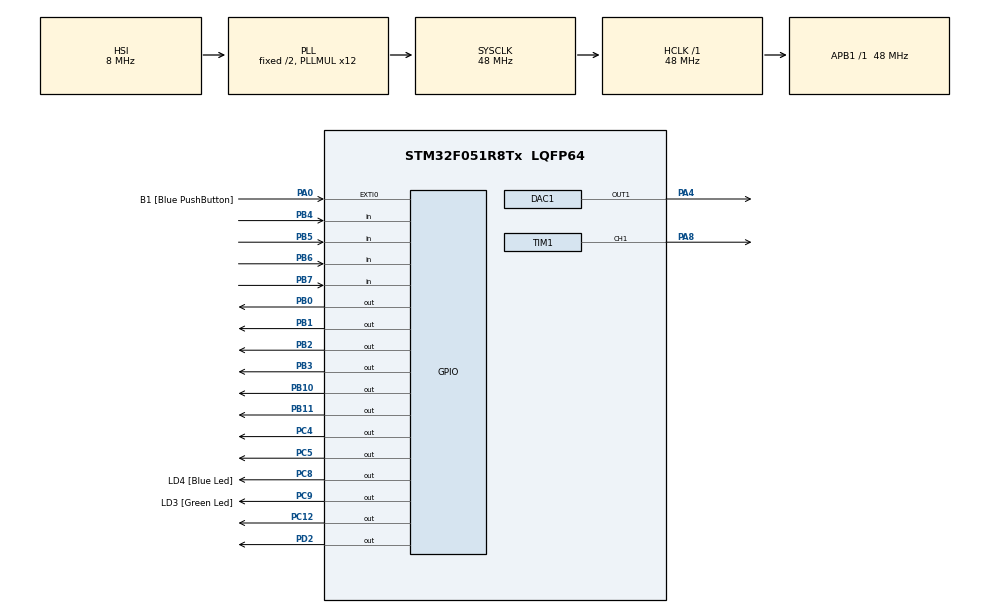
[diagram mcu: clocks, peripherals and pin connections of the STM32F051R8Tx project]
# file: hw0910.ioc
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Mcu.Family=STM32F0
Mcu.Name=STM32F051R8Tx
Mcu.Package=LQFP64
NVIC.TIM1_BRK_UP_TRG_COM_IRQn=true\:0\:0\:false\:false\:true\:true
NVIC.TIM1_CC_IRQn=true\:0\:0\:false\:false\:true\:true
NVIC.TIM2_IRQn=true\:0\:0\:false\:false\:true\:true
PA0.GPIO_Label=B1 [Blue PushButton]
PA0.GPIO_ModeDefaultEXTI=GPIO_MODE_EVT_RISING
PA0.Signal=GPXTI0
PA13.GPIO_Label=SWDIO
PA13.Signal=SYS_SWDIO
PA14.GPIO_Label=SWCLK
PA14.Signal=SYS_SWCLK
PA4.Signal=COMP_DAC11_group
PA8.Signal=S_TIM1_CH1
PB0.Signal=GPIO_Output
PB1.Signal=GPIO_Output
PB10.Signal=GPIO_Output
PB11.Signal=GPIO_Output
PB2.Signal=GPIO_Output
PB3.Signal=GPIO_Output
PB4.Signal=GPIO_Input
PB5.Signal=GPIO_Input
PB6.Signal=GPIO_Input
PB7.Signal=GPIO_Input
PC12.Signal=GPIO_Output
PC4.Signal=GPIO_Output
PC5.Signal=GPIO_Output
PC8.GPIO_Label=LD4 [Blue Led]
PC8.Signal=GPIO_Output
PC9.GPIO_Label=LD3 [Green Led]
PC9.Signal=GPIO_Output
PD2.Signal=GPIO_Output
ProjectManager.HeapSize=0x200
ProjectManager.StackSize=0x400
ProjectManager.TargetToolchain=SW4STM32
RCC.AHBFreq_Value=48000000
RCC.APB1Freq_Value=48000000
RCC.APB1TimFreq_Value=48000000
RCC.HCLKFreq_Value=48000000
RCC.PLLMUL=RCC_PLL_MUL12
RCC.SYSCLKFreq_VALUE=48000000
RCC.SYSCLKSource=RCC_SYSCLKSOURCE_PLLCLK
SH.COMP_DAC11_group.0=DAC1_OUT1,DAC_OUT1
SH.S_TIM1_CH1.0=TIM1_CH1,PWM Generation1 CH1
TIM1.Channel-PWM\ Generation1\ CH1=TIM_CHANNEL_1
TIM1.CounterMode=TIM_COUNTERMODE_CENTERALIGNED1
TIM1.Period=1024
TIM1.Prescaler=0
TIM2.Period=256
TIM2.Prescaler=47
TIM2.TIM_MasterOutputTrigger=TIM_TRGO_UPDATE
VP_TIM1_VS_ClockSourceINT.Mode=Internal
VP_TIM2_VS_ClockSourceINT.Mode=Internal
board=STM32F0DISCOVERY

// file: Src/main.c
/**
  ******************************************************************************
  * File Name          : main.c
  * Description        : Main program body
  ******************************************************************************
  ** This notice applies to any and all portions of this file
  * that are not between comment pairs USER CODE BEGIN and
  * USER CODE END. Other portions of this file, whether
  * inserted by the user or by software development tools
  * are owned by their respective copyright owners.
  *
  * COPYRIGHT(c) 2018 STMicroelectronics
  *
  * Redistribution and use in source and binary forms, with or without modification,
  * are permitted provided that the following conditions are met:
  *   1. Redistributions of source code must retain the above copyright notice,
  *      this list of conditions and the following disclaimer.
  *   2. Redistributions in binary form must reproduce the above copyright notice,
  *      this list of conditions and the following disclaimer in the documentation
  *      and/or other materials provided with the distribution.
  *   3. Neither the name of STMicroelectronics nor the names of its contributors
  *      may be used to endorse or promote products derived from this software
  *      without specific prior written permission.
  *
  * THIS SOFTWARE IS PROVIDED BY THE COPYRIGHT HOLDERS AND CONTRIBUTORS "AS IS"
  * AND ANY EXPRESS OR IMPLIED WARRANTIES, INCLUDING, BUT NOT LIMITED TO, THE
  * IMPLIED WARRANTIES OF MERCHANTABILITY AND FITNESS FOR A PARTICULAR PURPOSE ARE
  * DISCLAIMED. IN NO EVENT SHALL THE COPYRIGHT HOLDER OR CONTRIBUTORS BE LIABLE
  * FOR ANY DIRECT, INDIRECT, INCIDENTAL, SPECIAL, EXEMPLARY, OR CONSEQUENTIAL
  * DAMAGES (INCLUDING, BUT NOT LIMITED TO, PROCUREMENT OF SUBSTITUTE GOODS OR
  * SERVICES; LOSS OF USE, DATA, OR PROFITS; OR BUSINESS INTERRUPTION) HOWEVER
  * CAUSED AND ON ANY THEORY OF LIABILITY, WHETHER IN CONTRACT, STRICT LIABILITY,
  * OR TORT (INCLUDING NEGLIGENCE OR OTHERWISE) ARISING IN ANY WAY OUT OF THE USE
  * OF THIS SOFTWARE, EVEN IF ADVISED OF THE POSSIBILITY OF SUCH DAMAGE.
  *
  ******************************************************************************
  */
#include "main.h"
#include "stm32f0xx_hal.h"
/*extern int wavetab[125];
int temp;
*/

DAC_HandleTypeDef hdac1;

TIM_HandleTypeDef htim1;
TIM_HandleTypeDef htim2;

/* USER CODE BEGIN PV */
/* Private variables ---------------------------------------------------------*/

/* USER CODE END PV */

void SystemClock_Config(void);
static void MX_GPIO_Init(void);
static void MX_TIM1_Init(void);
static void MX_TIM2_Init(void);
static void MX_DAC1_Init(void);

void HAL_TIM_MspPostInit(TIM_HandleTypeDef *htim);

/* USER CODE BEGIN PFP */
/* Private function prototypes -----------------------------------------------*/

/* USER CODE END PFP */

int main(void)
{

  /* MCU Configuration----------------------------------------------------------*/

  /* Reset of all peripherals, Initializes the Flash interface and the Systick. */
  HAL_Init();

  /* Configure the system clock */
  SystemClock_Config();

  /* Initialize all configured peripherals */
  MX_GPIO_Init();
  MX_TIM1_Init();
  MX_TIM2_Init();
  MX_DAC1_Init();

  /* USER CODE BEGIN 2 */
  HAL_TIM_Base_Start_IT(&htim1);
  HAL_TIM_Base_Start_IT(&htim2);
  HAL_DAC_Start(&hdac1, DAC_CHANNEL_1);
  HAL_TIM_PWM_Start(&htim1, TIM_CHANNEL_1);
/*
  TIM_CCxChannelCmd(TIM1, TIM_CHANNEL_1, TIM_CCx_ENABLE);//enable
  HAL_TIM_Base_Start_IT(&htim1);//enable timer1
  __HAL_TIM_MOE_ENABLE(&htim1);//enable BDTR->Main output mode
  HAL_TIM_Base_Start_IT(&htim2);//enable timer2
  HAL_DAC_Start(&hdac1, DAC_CHANNEL_1);//enable dac
  */
  /* USER CODE END 2 */

  /* Infinite loop */
  while (1)
  {

  }

}

/** System Clock Configuration
*/
void SystemClock_Config(void)
{

  RCC_OscInitTypeDef RCC_OscInitStruct;
  RCC_ClkInitTypeDef RCC_ClkInitStruct;

    /**Initializes the CPU, AHB and APB busses clocks
    */
  RCC_OscInitStruct.OscillatorType = RCC_OSCILLATORTYPE_HSI;
  RCC_OscInitStruct.HSIState = RCC_HSI_ON;
  RCC_OscInitStruct.HSICalibrationValue = 16;
  RCC_OscInitStruct.PLL.PLLState = RCC_PLL_ON;
  RCC_OscInitStruct.PLL.PLLSource = RCC_PLLSOURCE_HSI;
  RCC_OscInitStruct.PLL.PLLMUL = RCC_PLL_MUL12;
  RCC_OscInitStruct.PLL.PREDIV = RCC_PREDIV_DIV1;
  if (HAL_RCC_OscConfig(&RCC_OscInitStruct) != HAL_OK)
  {
    _Error_Handler(__FILE__, __LINE__);
  }

    /**Initializes the CPU, AHB and APB busses clocks
    */
  RCC_ClkInitStruct.ClockType = RCC_CLOCKTYPE_HCLK|RCC_CLOCKTYPE_SYSCLK
                              |RCC_CLOCKTYPE_PCLK1;
  RCC_ClkInitStruct.SYSCLKSource = RCC_SYSCLKSOURCE_PLLCLK;
  RCC_ClkInitStruct.AHBCLKDivider = RCC_SYSCLK_DIV1;
  RCC_ClkInitStruct.APB1CLKDivider = RCC_HCLK_DIV1;

  if (HAL_RCC_ClockConfig(&RCC_ClkInitStruct, FLASH_LATENCY_1) != HAL_OK)
  {
    _Error_Handler(__FILE__, __LINE__);
  }

    /**Configure the Systick interrupt time
    */
  HAL_SYSTICK_Config(HAL_RCC_GetHCLKFreq()/1000);

    /**Configure the Systick
    */
  HAL_SYSTICK_CLKSourceConfig(SYSTICK_CLKSOURCE_HCLK);

  /* SysTick_IRQn interrupt configuration */
  HAL_NVIC_SetPriority(SysTick_IRQn, 0, 0);
}

/* DAC1 init function */
static void MX_DAC1_Init(void)
{

  DAC_ChannelConfTypeDef sConfig;

    /**DAC Initialization
    */
  hdac1.Instance = DAC;
  if (HAL_DAC_Init(&hdac1) != HAL_OK)
  {
    _Error_Handler(__FILE__, __LINE__);
  }

    /**DAC channel OUT1 config
    */
  sConfig.DAC_Trigger = DAC_TRIGGER_NONE;
  sConfig.DAC_OutputBuffer = DAC_OUTPUTBUFFER_ENABLE;
  if (HAL_DAC_ConfigChannel(&hdac1, &sConfig, DAC_CHANNEL_1) != HAL_OK)
  {
    _Error_Handler(__FILE__, __LINE__);
  }

}

/* TIM1 init function */
static void MX_TIM1_Init(void)
{

  TIM_ClockConfigTypeDef sClockSourceConfig;
  TIM_MasterConfigTypeDef sMasterConfig;
  TIM_OC_InitTypeDef sConfigOC;
  TIM_BreakDeadTimeConfigTypeDef sBreakDeadTimeConfig;

  htim1.Instance = TIM1;
  htim1.Init.Prescaler = 0;
  htim1.Init.CounterMode = TIM_COUNTERMODE_CENTERALIGNED1;
  htim1.Init.Period = 1024;
  htim1.Init.ClockDivision = TIM_CLOCKDIVISION_DIV1;
  htim1.Init.RepetitionCounter = 0;
  htim1.Init.AutoReloadPreload = TIM_AUTORELOAD_PRELOAD_DISABLE;
  if (HAL_TIM_Base_Init(&htim1) != HAL_OK)
  {
    _Error_Handler(__FILE__, __LINE__);
  }

  sClockSourceConfig.ClockSource = TIM_CLOCKSOURCE_INTERNAL;
  if (HAL_TIM_ConfigClockSource(&htim1, &sClockSourceConfig) != HAL_OK)
  {
    _Error_Handler(__FILE__, __LINE__);
  }

  if (HAL_TIM_PWM_Init(&htim1) != HAL_OK)
  {
    _Error_Handler(__FILE__, __LINE__);
  }

  sMasterConfig.MasterOutputTrigger = TIM_TRGO_RESET;
  sMasterConfig.MasterSlaveMode = TIM_MASTERSLAVEMODE_DISABLE;
  if (HAL_TIMEx_MasterConfigSynchronization(&htim1, &sMasterConfig) != HAL_OK)
  {
    _Error_Handler(__FILE__, __LINE__);
  }

  sConfigOC.OCMode = TIM_OCMODE_PWM1;
  sConfigOC.Pulse = 0;
  sConfigOC.OCPolarity = TIM_OCPOLARITY_HIGH;
  sConfigOC.OCNPolarity = TIM_OCNPOLARITY_HIGH;
  sConfigOC.OCFastMode = TIM_OCFAST_DISABLE;
  sConfigOC.OCIdleState = TIM_OCIDLESTATE_RESET;
  sConfigOC.OCNIdleState = TIM_OCNIDLESTATE_RESET;
  if (HAL_TIM_PWM_ConfigChannel(&htim1, &sConfigOC, TIM_CHANNEL_1) != HAL_OK)
  {
    _Error_Handler(__FILE__, __LINE__);
  }

  sBreakDeadTimeConfig.OffStateRunMode = TIM_OSSR_DISABLE;
  sBreakDeadTimeConfig.OffStateIDLEMode = TIM_OSSI_DISABLE;
  sBreakDeadTimeConfig.LockLevel = TIM_LOCKLEVEL_OFF;
  sBreakDeadTimeConfig.DeadTime = 0;
  sBreakDeadTimeConfig.BreakState = TIM_BREAK_DISABLE;
  sBreakDeadTimeConfig.BreakPolarity = TIM_BREAKPOLARITY_HIGH;
  sBreakDeadTimeConfig.AutomaticOutput = TIM_AUTOMATICOUTPUT_DISABLE;
  if (HAL_TIMEx_ConfigBreakDeadTime(&htim1, &sBreakDeadTimeConfig) != HAL_OK)
  {
    _Error_Handler(__FILE__, __LINE__);
  }

  HAL_TIM_MspPostInit(&htim1);

}

/* TIM2 init function */
static void MX_TIM2_Init(void)
{

  TIM_ClockConfigTypeDef sClockSourceConfig;
  TIM_MasterConfigTypeDef sMasterConfig;

  htim2.Instance = TIM2;
  htim2.Init.Prescaler = 47;
  htim2.Init.CounterMode = TIM_COUNTERMODE_UP;
  htim2.Init.Period = 256;
  htim2.Init.ClockDivision = TIM_CLOCKDIVISION_DIV1;
  htim2.Init.AutoReloadPreload = TIM_AUTORELOAD_PRELOAD_DISABLE;
  if (HAL_TIM_Base_Init(&htim2) != HAL_OK)
  {
    _Error_Handler(__FILE__, __LINE__);
  }

  sClockSourceConfig.ClockSource = TIM_CLOCKSOURCE_INTERNAL;
  if (HAL_TIM_ConfigClockSource(&htim2, &sClockSourceConfig) != HAL_OK)
  {
    _Error_Handler(__FILE__, __LINE__);
  }

  sMasterConfig.MasterOutputTrigger = TIM_TRGO_UPDATE;
  sMasterConfig.MasterSlaveMode = TIM_MASTERSLAVEMODE_DISABLE;
  if (HAL_TIMEx_MasterConfigSynchronization(&htim2, &sMasterConfig) != HAL_OK)
  {
    _Error_Handler(__FILE__, __LINE__);
  }

}

/** Configure pins as
        * Analog
        * Input
        * Output
        * EVENT_OUT
        * EXTI
*/
static void MX_GPIO_Init(void)
{

  GPIO_InitTypeDef GPIO_InitStruct;

  /* GPIO Ports Clock Enable */
  __HAL_RCC_GPIOA_CLK_ENABLE();
  __HAL_RCC_GPIOC_CLK_ENABLE();
  __HAL_RCC_GPIOB_CLK_ENABLE();
  __HAL_RCC_GPIOD_CLK_ENABLE();

  /*Configure GPIO pin Output Level */
  HAL_GPIO_WritePin(GPIOC, GPIO_PIN_4|GPIO_PIN_5|LD4_Pin|LD3_Pin
                          |GPIO_PIN_12, GPIO_PIN_RESET);

  /*Configure GPIO pin Output Level */
  HAL_GPIO_WritePin(GPIOB, GPIO_PIN_0|GPIO_PIN_1|GPIO_PIN_2|GPIO_PIN_10
                          |GPIO_PIN_11|GPIO_PIN_3, GPIO_PIN_RESET);

  /*Configure GPIO pin Output Level */
  HAL_GPIO_WritePin(GPIOD, GPIO_PIN_2, GPIO_PIN_RESET);

  /*Configure GPIO pin : B1_Pin */
  GPIO_InitStruct.Pin = B1_Pin;
  GPIO_InitStruct.Mode = GPIO_MODE_EVT_RISING;
  GPIO_InitStruct.Pull = GPIO_NOPULL;
  HAL_GPIO_Init(B1_GPIO_Port, &GPIO_InitStruct);

  /*Configure GPIO pins : PC4 PC5 LD4_Pin LD3_Pin
                           PC12 */
  GPIO_InitStruct.Pin = GPIO_PIN_4|GPIO_PIN_5|LD4_Pin|LD3_Pin
                          |GPIO_PIN_12;
  GPIO_InitStruct.Mode = GPIO_MODE_OUTPUT_PP;
  GPIO_InitStruct.Pull = GPIO_NOPULL;
  GPIO_InitStruct.Speed = GPIO_SPEED_FREQ_LOW;
  HAL_GPIO_Init(GPIOC, &GPIO_InitStruct);

  /*Configure GPIO pins : PB0 PB1 PB2 PB10
                           PB11 PB3 */
  GPIO_InitStruct.Pin = GPIO_PIN_0|GPIO_PIN_1|GPIO_PIN_2|GPIO_PIN_10
                          |GPIO_PIN_11|GPIO_PIN_3;
  GPIO_InitStruct.Mode = GPIO_MODE_OUTPUT_PP;
  GPIO_InitStruct.Pull = GPIO_NOPULL;
  GPIO_InitStruct.Speed = GPIO_SPEED_FREQ_LOW;
  HAL_GPIO_Init(GPIOB, &GPIO_InitStruct);

  /*Configure GPIO pin : PD2 */
  GPIO_InitStruct.Pin = GPIO_PIN_2;
  GPIO_InitStruct.Mode = GPIO_MODE_OUTPUT_PP;
  GPIO_InitStruct.Pull = GPIO_NOPULL;
  GPIO_InitStruct.Speed = GPIO_SPEED_FREQ_LOW;
  HAL_GPIO_Init(GPIOD, &GPIO_InitStruct);

  /*Configure GPIO pins : PB4 PB5 PB6 PB7 */
  GPIO_InitStruct.Pin = GPIO_PIN_4|GPIO_PIN_5|GPIO_PIN_6|GPIO_PIN_7;
  GPIO_InitStruct.Mode = GPIO_MODE_INPUT;
  GPIO_InitStruct.Pull = GPIO_NOPULL;
  HAL_GPIO_Init(GPIOB, &GPIO_InitStruct);

}

void _Error_Handler(char * file, int line)
{
  while(1)
  {
  }
}

/************************ (C) COPYRIGHT STMicroelectronics *****END OF FILE****/
